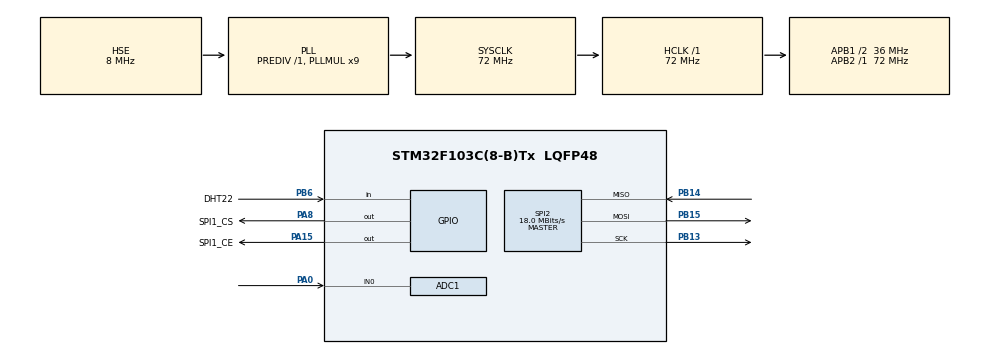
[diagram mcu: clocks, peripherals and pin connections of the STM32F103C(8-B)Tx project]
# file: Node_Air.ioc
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ADC1.Channel-1\#ChannelRegularConversion=ADC_CHANNEL_0
ADC1.ContinuousConvMode=DISABLE
ADC1.NbrOfConversion=1
ADC1.NbrOfConversionFlag=1
ADC1.Rank-1\#ChannelRegularConversion=1
ADC1.SamplingTime-1\#ChannelRegularConversion=ADC_SAMPLETIME_239CYCLES_5
ADC1.master=1
Dma.ADC1.0.Direction=DMA_PERIPH_TO_MEMORY
Dma.ADC1.0.Instance=DMA1_Channel1
Dma.ADC1.0.MemDataAlignment=DMA_MDATAALIGN_HALFWORD
Dma.ADC1.0.MemInc=DMA_MINC_ENABLE
Dma.ADC1.0.Mode=DMA_CIRCULAR
Dma.ADC1.0.PeriphDataAlignment=DMA_PDATAALIGN_HALFWORD
Dma.ADC1.0.PeriphInc=DMA_PINC_DISABLE
Dma.ADC1.0.Priority=DMA_PRIORITY_LOW
Dma.Request0=ADC1
Mcu.Family=STM32F1
Mcu.Name=STM32F103C(8-B)Tx
Mcu.Package=LQFP48
NVIC.DMA1_Channel1_IRQn=true\:0\:0\:false\:false\:true\:false\:true\:true
NVIC.PriorityGroup=NVIC_PRIORITYGROUP_4
PA0-WKUP.Signal=ADCx_IN0
PA13.Mode=Serial_Wire
PA13.Signal=SYS_JTMS-SWDIO
PA14.Mode=Serial_Wire
PA14.Signal=SYS_JTCK-SWCLK
PA15.GPIO_Label=SPI1_CE
PA15.GPIO_ModeDefaultOutputPP=GPIO_MODE_OUTPUT_PP
PA15.GPIO_PuPd=GPIO_PULLUP
PA15.GPIO_Speed=GPIO_SPEED_FREQ_HIGH
PA15.PinState=GPIO_PIN_RESET
PA15.Signal=GPIO_Output
PA8.GPIO_Label=SPI1_CS
PA8.GPIO_ModeDefaultOutputPP=GPIO_MODE_OUTPUT_PP
PA8.GPIO_PuPd=GPIO_PULLUP
PA8.GPIO_Speed=GPIO_SPEED_FREQ_HIGH
PA8.PinState=GPIO_PIN_RESET
PA8.Signal=GPIO_Output
PB13.Mode=Full_Duplex_Master
PB13.Signal=SPI2_SCK
PB14.Mode=Full_Duplex_Master
PB14.Signal=SPI2_MISO
PB15.Mode=Full_Duplex_Master
PB15.Signal=SPI2_MOSI
PB6.GPIO_Label=DHT22
PB6.GPIO_PuPd=GPIO_NOPULL
PB6.Signal=GPIO_Input
PD0-OSC_IN.Mode=HSE-External-Oscillator
PD0-OSC_IN.Signal=RCC_OSC_IN
PD1-OSC_OUT.Mode=HSE-External-Oscillator
PD1-OSC_OUT.Signal=RCC_OSC_OUT
ProjectManager.HeapSize=0x200
ProjectManager.StackSize=0x400
ProjectManager.TargetToolchain=MDK-ARM V5.32
RCC.ADCPresc=RCC_ADCPCLK2_DIV6
RCC.AHBFreq_Value=72000000
RCC.APB1CLKDivider=RCC_HCLK_DIV2
RCC.APB1Freq_Value=36000000
RCC.APB1TimFreq_Value=72000000
RCC.APB2Freq_Value=72000000
RCC.APB2TimFreq_Value=72000000
RCC.HCLKFreq_Value=72000000
RCC.PLLMUL=RCC_PLL_MUL9
RCC.PLLSourceVirtual=RCC_PLLSOURCE_HSE
RCC.SYSCLKFreq_VALUE=72000000
RCC.SYSCLKSource=RCC_SYSCLKSOURCE_PLLCLK
RCC.USBFreq_Value=72000000
SH.ADCx_IN0.0=ADC1_IN0,IN0
SPI2.CalculateBaudRate=18.0 MBits/s
SPI2.Direction=SPI_DIRECTION_2LINES
SPI2.Mode=SPI_MODE_MASTER
SPI2.VirtualType=VM_MASTER
TIM4.Prescaler=71
VP_TIM4_VS_ClockSourceINT.Mode=Internal
board=custom

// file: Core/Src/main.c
/* USER CODE BEGIN Header */
/**
  ******************************************************************************
  * @file           : main.c
  * @brief          : Main program body
  ******************************************************************************
  * @attention
  *
  * Copyright (c) 2024 STMicroelectronics.
  * All rights reserved.
  *
  * This software is licensed under terms that can be found in the LICENSE file
  * in the root directory of this software component.
  * If no LICENSE file comes with this software, it is provided AS-IS.
  *
  ******************************************************************************
  */
/* USER CODE END Header */
#include "main.h"
#include "delay.h"
#include "DHT22.h"
#include "MY_NRF24.h"
#include "MQ135.h"

/* USER CODE BEGIN PTD */

typedef struct {
	char ID;
	float nhietDo;
	float doAm;
	float CO2;
}Data_Air_t;

/* USER CODE END PTD */

ADC_HandleTypeDef hadc1;
DMA_HandleTypeDef hdma_adc1;

SPI_HandleTypeDef hspi2;

TIM_HandleTypeDef htim4;

const uint64_t Address_NodeRoom = 0x1122334422;

uint16_t Buffer_ADC;

uint32_t lastDelay = 0;
uint16_t count = 0;

uint8_t buffer[32];

void SystemClock_Config(void);
static void MX_GPIO_Init(void);
static void MX_DMA_Init(void);
static void MX_ADC1_Init(void);
static void MX_TIM4_Init(void);
static void MX_SPI2_Init(void);

int main(void)
{
  /* MCU Configuration--------------------------------------------------------*/
  /* Reset of all peripherals, Initializes the Flash interface and the Systick. */
  HAL_Init();
  /* Configure the system clock */
  SystemClock_Config();
  /* Initialize all configured peripherals */
  MX_GPIO_Init();
  MX_DMA_Init();
  MX_ADC1_Init();
  MX_TIM4_Init();
  MX_SPI2_Init();
  /* USER CODE BEGIN 2 */
	HAL_TIM_Base_Start(&htim4);
	HAL_ADC_Start_DMA(&hadc1, (uint32_t *) &Buffer_ADC, 1);

	NRF24_Begin(hspi2, GPIOA, SPI1_CS_Pin, SPI1_CE_Pin);
	NRF24_OpenWritingPipe(Address_NodeRoom);
	NRF24_SetPALevel(RF24_PA_0dB);
	NRF24_SetDataRate(RF24_250KBPS);
	NRF24_SetChannel(52);
	NRF24_EnableDynamicPayloads();
	NRF24_SetAutoAck(true);
	NRF24_StartListening();

  /* USER CODE END 2 */
  /* Infinite loop */
  /* USER CODE BEGIN WHILE */

  while (1)
  {

	if( (uint32_t)(HAL_GetTick() - lastDelay) > 5000)
	{
		bool b_Status_DHT;
		Data_Air_t Value_Air;
		Value_Air.ID = 'C';
		// Read value temperature and humidity from DHT22
		b_Status_DHT = DHT22_Start();
		if(b_Status_DHT){
			DHT22_Read();
			Value_Air.nhietDo = DHT22_Temperature();
			Value_Air.doAm = DHT22_Humidity();
		} else {
			Value_Air.nhietDo = -99.0f;
			Value_Air.doAm = -99.0f;
		}
		Value_Air.CO2 = MQ135_GetPPM();
		// Send data from node 1.1 to node 1
		NRF24_StopListening();
		NRF24_Write(&Value_Air, sizeof(Value_Air));
		NRF24_StartListening();
		lastDelay = HAL_GetTick();
	}
	if(Buffer_ADC > 2000) {
		HAL_GPIO_WritePin(Buzzer_GPIO_Port, Buzzer_Pin, GPIO_PIN_RESET);
	} else {
		HAL_GPIO_WritePin(Buzzer_GPIO_Port, Buzzer_Pin, GPIO_PIN_SET);
	}

	if(NRF24_Available()){
		NRF24_Read(buffer,32);
		if(buffer[1] % 2 == 0){
			HAL_GPIO_WritePin(GPIOC, GPIO_PIN_13, GPIO_PIN_SET);
		} else {
			HAL_GPIO_WritePin(GPIOC, GPIO_PIN_13, GPIO_PIN_RESET);
		}
	}
  }
  /* USER CODE END 3 */
}

void SystemClock_Config(void)
{
  RCC_OscInitTypeDef RCC_OscInitStruct = {0};
  RCC_ClkInitTypeDef RCC_ClkInitStruct = {0};
  RCC_PeriphCLKInitTypeDef PeriphClkInit = {0};

  /** Initializes the RCC Oscillators according to the specified parameters
  * in the RCC_OscInitTypeDef structure.
  */
  RCC_OscInitStruct.OscillatorType = RCC_OSCILLATORTYPE_HSE;
  RCC_OscInitStruct.HSEState = RCC_HSE_ON;
  RCC_OscInitStruct.HSEPredivValue = RCC_HSE_PREDIV_DIV1;
  RCC_OscInitStruct.HSIState = RCC_HSI_ON;
  RCC_OscInitStruct.PLL.PLLState = RCC_PLL_ON;
  RCC_OscInitStruct.PLL.PLLSource = RCC_PLLSOURCE_HSE;
  RCC_OscInitStruct.PLL.PLLMUL = RCC_PLL_MUL9;
  if (HAL_RCC_OscConfig(&RCC_OscInitStruct) != HAL_OK)
  {
    Error_Handler();
  }

  /** Initializes the CPU, AHB and APB buses clocks
  */
  RCC_ClkInitStruct.ClockType = RCC_CLOCKTYPE_HCLK|RCC_CLOCKTYPE_SYSCLK
                              |RCC_CLOCKTYPE_PCLK1|RCC_CLOCKTYPE_PCLK2;
  RCC_ClkInitStruct.SYSCLKSource = RCC_SYSCLKSOURCE_PLLCLK;
  RCC_ClkInitStruct.AHBCLKDivider = RCC_SYSCLK_DIV1;
  RCC_ClkInitStruct.APB1CLKDivider = RCC_HCLK_DIV2;
  RCC_ClkInitStruct.APB2CLKDivider = RCC_HCLK_DIV1;

  if (HAL_RCC_ClockConfig(&RCC_ClkInitStruct, FLASH_LATENCY_2) != HAL_OK)
  {
    Error_Handler();
  }
  PeriphClkInit.PeriphClockSelection = RCC_PERIPHCLK_ADC;
  PeriphClkInit.AdcClockSelection = RCC_ADCPCLK2_DIV6;
  if (HAL_RCCEx_PeriphCLKConfig(&PeriphClkInit) != HAL_OK)
  {
    Error_Handler();
  }
}

static void MX_ADC1_Init(void)
{

  ADC_ChannelConfTypeDef sConfig = {0};

  /** Common config
  */
  hadc1.Instance = ADC1;
  hadc1.Init.ScanConvMode = ADC_SCAN_DISABLE;
  hadc1.Init.ContinuousConvMode = ENABLE;
  hadc1.Init.DiscontinuousConvMode = DISABLE;
  hadc1.Init.ExternalTrigConv = ADC_SOFTWARE_START;
  hadc1.Init.DataAlign = ADC_DATAALIGN_RIGHT;
  hadc1.Init.NbrOfConversion = 1;
  if (HAL_ADC_Init(&hadc1) != HAL_OK)
  {
    Error_Handler();
  }

  /** Configure Regular Channel
  */
  sConfig.Channel = ADC_CHANNEL_0;
  sConfig.Rank = ADC_REGULAR_RANK_1;
  sConfig.SamplingTime = ADC_SAMPLETIME_239CYCLES_5;
  if (HAL_ADC_ConfigChannel(&hadc1, &sConfig) != HAL_OK)
  {
    Error_Handler();
  }

}

static void MX_SPI2_Init(void)
{

  /* SPI2 parameter configuration*/
  hspi2.Instance = SPI2;
  hspi2.Init.Mode = SPI_MODE_MASTER;
  hspi2.Init.Direction = SPI_DIRECTION_2LINES;
  hspi2.Init.DataSize = SPI_DATASIZE_8BIT;
  hspi2.Init.CLKPolarity = SPI_POLARITY_LOW;
  hspi2.Init.CLKPhase = SPI_PHASE_1EDGE;
  hspi2.Init.NSS = SPI_NSS_SOFT;
  hspi2.Init.BaudRatePrescaler = SPI_BAUDRATEPRESCALER_2;
  hspi2.Init.FirstBit = SPI_FIRSTBIT_MSB;
  hspi2.Init.TIMode = SPI_TIMODE_DISABLE;
  hspi2.Init.CRCCalculation = SPI_CRCCALCULATION_DISABLE;
  hspi2.Init.CRCPolynomial = 10;
  if (HAL_SPI_Init(&hspi2) != HAL_OK)
  {
    Error_Handler();
  }

}

static void MX_TIM4_Init(void)
{

  TIM_ClockConfigTypeDef sClockSourceConfig = {0};
  TIM_MasterConfigTypeDef sMasterConfig = {0};

  htim4.Instance = TIM4;
  htim4.Init.Prescaler = 71;
  htim4.Init.CounterMode = TIM_COUNTERMODE_UP;
  htim4.Init.Period = 65535;
  htim4.Init.ClockDivision = TIM_CLOCKDIVISION_DIV1;
  htim4.Init.AutoReloadPreload = TIM_AUTORELOAD_PRELOAD_DISABLE;
  if (HAL_TIM_Base_Init(&htim4) != HAL_OK)
  {
    Error_Handler();
  }
  sClockSourceConfig.ClockSource = TIM_CLOCKSOURCE_INTERNAL;
  if (HAL_TIM_ConfigClockSource(&htim4, &sClockSourceConfig) != HAL_OK)
  {
    Error_Handler();
  }
  sMasterConfig.MasterOutputTrigger = TIM_TRGO_RESET;
  sMasterConfig.MasterSlaveMode = TIM_MASTERSLAVEMODE_DISABLE;
  if (HAL_TIMEx_MasterConfigSynchronization(&htim4, &sMasterConfig) != HAL_OK)
  {
    Error_Handler();
  }

}

static void MX_DMA_Init(void)
{

  /* DMA controller clock enable */
  __HAL_RCC_DMA1_CLK_ENABLE();

  /* DMA interrupt init */
  /* DMA1_Channel1_IRQn interrupt configuration */
  HAL_NVIC_SetPriority(DMA1_Channel1_IRQn, 0, 0);
  HAL_NVIC_EnableIRQ(DMA1_Channel1_IRQn);

}

static void MX_GPIO_Init(void)
{
  GPIO_InitTypeDef GPIO_InitStruct = {0};

  /* GPIO Ports Clock Enable */
  __HAL_RCC_GPIOD_CLK_ENABLE();
  __HAL_RCC_GPIOA_CLK_ENABLE();
  __HAL_RCC_GPIOB_CLK_ENABLE();
  __HAL_RCC_GPIOC_CLK_ENABLE();

  /*Configure GPIO pin Output Level */
  HAL_GPIO_WritePin(GPIOA, SPI1_CS_Pin|SPI1_CE_Pin, GPIO_PIN_RESET);
  HAL_GPIO_WritePin(GPIOB, Buzzer_Pin, GPIO_PIN_SET);

  /*Configure GPIO pins : SPI1_CS_Pin SPI1_CE_Pin */
  GPIO_InitStruct.Pin = SPI1_CS_Pin|SPI1_CE_Pin;
  GPIO_InitStruct.Mode = GPIO_MODE_OUTPUT_PP;
  GPIO_InitStruct.Pull = GPIO_PULLUP;
  GPIO_InitStruct.Speed = GPIO_SPEED_FREQ_HIGH;
  HAL_GPIO_Init(GPIOA, &GPIO_InitStruct);

  /*Configure GPIO pin : Buzzer */
  GPIO_InitStruct.Pin = GPIO_PIN_8;
  GPIO_InitStruct.Mode = GPIO_MODE_OUTPUT_PP;
  GPIO_InitStruct.Pull = GPIO_PULLUP;
  HAL_GPIO_Init(GPIOB, &GPIO_InitStruct);

}

void Error_Handler(void)
{
  __disable_irq();
  while (1)
  {
  }
}
